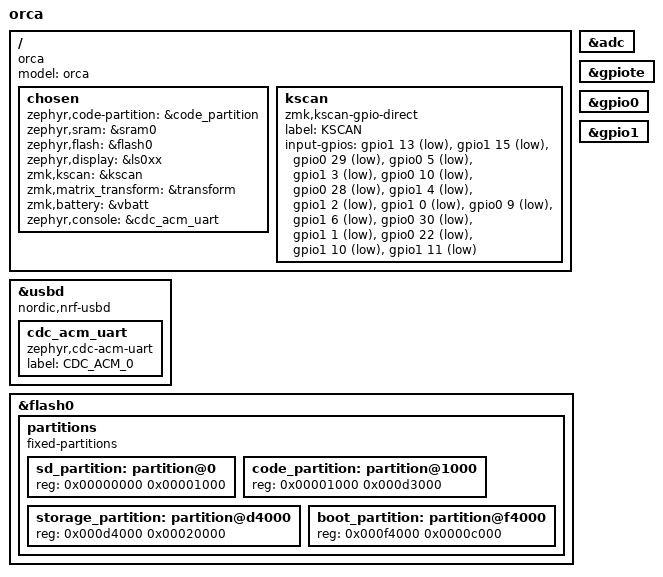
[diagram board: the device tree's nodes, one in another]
/* 
 *  Created by Hugh Lam (2024)
 *
 *  orca .dts file.
 */

// /dts-v1/;
#include "orca_base.dts"

    // RGB pins
    // spi3_default: spi3_default {
    //     group1 {
    //         psels = <NRF_PSEL(SPIM_MOSI, 0, 21)>;
    //     };
    // };

    // spi3_sleep: spi3_sleep {
    //     group1 {
    //         psels = <NRF_PSEL(SPIM_MOSI, 0, 21)>;
    //         low-power-enable;
    //     };
    // };


/ {
    model = "orca";
    compatible = "orca";
    chosen {
        zephyr,code-partition = &code_partition;
		zephyr,sram = &sram0;
		zephyr,flash = &flash0;
		zephyr,display = &ls0xx;
		zmk,kscan = &kscan;
		zmk,matrix_transform = &transform;
		zmk,battery = &vbatt;
		zephyr,console = &cdc_acm_uart;
        // zmk,underglow = &led_strip;
    };

    kscan: kscan {
		compatible = "zmk,kscan-gpio-direct";
		label = "KSCAN";

        input-gpios
            = <&gpio1 13 (GPIO_ACTIVE_LOW | GPIO_PULL_UP)>  // 1
            , <&gpio1 15 (GPIO_ACTIVE_LOW | GPIO_PULL_UP)>  // 2
            , <&gpio0 29 (GPIO_ACTIVE_LOW | GPIO_PULL_UP)>  // 3    at 0V
            , <&gpio0  5 (GPIO_ACTIVE_LOW | GPIO_PULL_UP)>  // ...
            , <&gpio1  3 (GPIO_ACTIVE_LOW | GPIO_PULL_UP)>

            , <&gpio0 10 (GPIO_ACTIVE_LOW | GPIO_PULL_UP)>
            , <&gpio0 28 (GPIO_ACTIVE_LOW | GPIO_PULL_UP)>
            , <&gpio1  4 (GPIO_ACTIVE_LOW | GPIO_PULL_UP)>  // at ~ 1V
            , <&gpio1  2 (GPIO_ACTIVE_LOW | GPIO_PULL_UP)>
            , <&gpio1  0 (GPIO_ACTIVE_LOW | GPIO_PULL_UP)>

            , <&gpio0  9 (GPIO_ACTIVE_LOW | GPIO_PULL_UP)>
            , <&gpio1  6 (GPIO_ACTIVE_LOW | GPIO_PULL_UP)>
            , <&gpio0 30 (GPIO_ACTIVE_LOW | GPIO_PULL_UP)>
            , <&gpio1  1 (GPIO_ACTIVE_LOW | GPIO_PULL_UP)>
            , <&gpio0 22 (GPIO_ACTIVE_LOW | GPIO_PULL_UP)>

            , <&gpio1  10 (GPIO_ACTIVE_LOW | GPIO_PULL_UP)>  // 16
            , <&gpio1  11 (GPIO_ACTIVE_LOW | GPIO_PULL_UP)>  // 17  at 0V
            ;
	};
};

&adc {
	status = "okay";
};

&gpiote {
	status = "okay";
};

&gpio0 {
	status = "okay";
    // troubleshoot0 {
    //     gpio-hog;
    //     gpios = <29 GPIO_ACTIVE_HIGH>;
    //     output-high;
    // };
};

&gpio1 {
	status = "okay";
    // troubleshoot1 {
    //     gpio-hog;
    //     gpios = <4 GPIO_ACTIVE_HIGH>,   // isn't connected to its switch socket, however socket seems to be sourcing 1V from somewhere?
    //
};         
// &spi3 {
//   compatible = "nordic,nrf-spim";
//   status = "okay";

//   pinctrl-0 = <&spi3_default>;
//   pinctrl-1 = <&spi3_sleep>;
//   pinctrl-names = "default", "sleep";

//   led_strip: ws2812@0 {
//     compatible = "worldsemi,ws2812-spi";

//     /* SPI */
//     reg = <0>; /* ignored, but necessary for SPI bindings */
//     spi-max-frequency = <4000000>;

//     /* WS2812 */
//     chain-length = <17>; /* number of LEDs */
//     spi-on

&usbd {
  status = "okay";
  compatible = "nordic,nrf-usbd";
  cdc_acm_uart: cdc_acm_uart {
    compatible = "zephyr,cdc-acm-uart";
    label = "CDC_ACM_0";
  };
};

&flash0 {
	/*
	 * For more information, see:
	 * http://docs.zephyrproject.org/latest/devices/dts/flash_partitions.html
	 */
	partitions {
		compatible = "fixed-partitions";
		#address-cells = <1>;
		#size-cells = <1>;

		sd_partition: partition@0 {
			reg = <0x00000000 0x00001000>;
		};
		code_partition: partition@1000 {
			reg = <0x00001000 0x000d3000>;
		};

		storage_partition: partition@d4000 {
			reg = <0x000d4000 0x00020000>;
		};

		boot_partition: partition@f4000 {
			reg = <0x000f4000 0x0000c000>;
		};
	};
};
